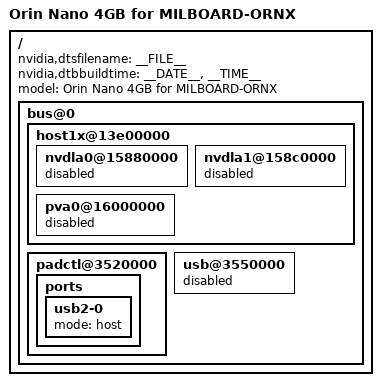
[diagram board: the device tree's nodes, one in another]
// SPDX-License-Identifier: GPL-2.0-only
// SPDX-FileCopyrightText: Copyright (c) 2023-2024, NVIDIA CORPORATION & AFFILIATES.  All rights reserved.

/dts-v1/;

#include "staging/tegra234-p3768-0000+p3767-0004.dts"
#include "tegra234-p3768-0000+p3767-xxxx-nv-common.dtsi"
#include "tegra234-p3768-0000-milboard-ornx.dtsi"

/ {
	nvidia,dtsfilename = __FILE__;
	nvidia,dtbbuildtime = __DATE__, __TIME__;
	model = "Orin Nano 4GB for MILBOARD-ORNX";

	bus@0 {
		host1x@13e00000 {
			nvdla0@15880000 {
				status = "disabled";
			};

			nvdla1@158c0000 {
				status = "disabled";
			};

			pva0@16000000 {
				status = "disabled";
			};
		};

		padctl@3520000 {
			ports {
				usb2-0 {/* Goes to recovery port */
					mode = "host";
					/delete-property/ usb-role-switch;
					/delete-node/ connector;
				};
			};
		};
		usb@3550000 {
			status = "disabled";
		};
	};
};
